# DSI1_A register map
Vendor: Texas Instruments
Peripheral module from a debugger description file (folder omap5430_ES2_PUBLIC).
Registers are 32-bit, access per field, reset 0x0 unless marked. A register's access mark holds for its fields unless they carry their own. Offsets are as the file gives them; lines under a group give offsets from that group; [hi:lo] are bit positions; {n}, {i} and the like mark numbered series; 'fields as' and 'values as' point back to an identical list; <NAME> marks a mode.

## DSI1_A (part 1 of 2)
0x00 DSI_REVISION ro reset not defined — IP Revision
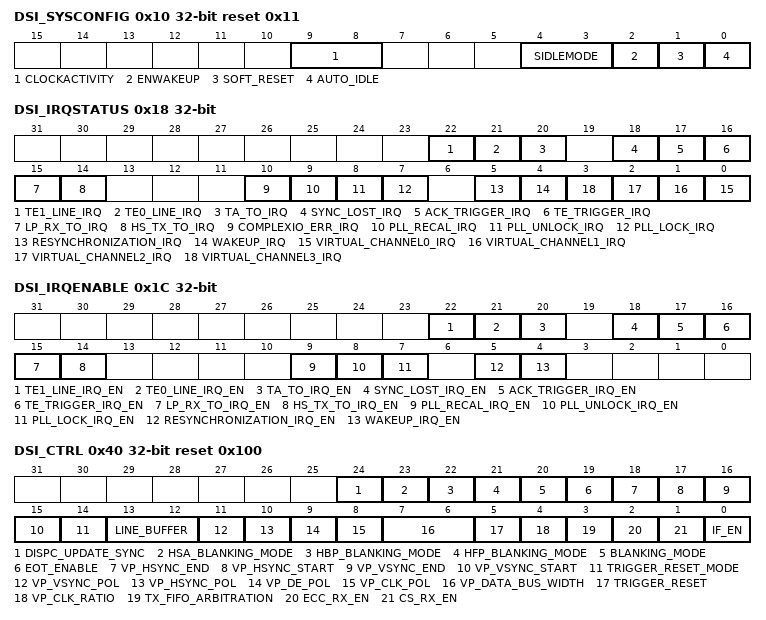
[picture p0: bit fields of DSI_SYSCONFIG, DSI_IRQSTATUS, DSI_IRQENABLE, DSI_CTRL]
0x10 DSI_SYSCONFIG reset 0x11 — System configuration register
  [9:8] CLOCKACTIVITY rw — Clock activity during wake-up mode period
    0=OCPFuncOff (Interface and functional clocks can be switched off.); 1=FuncOff (Functional clocks can be switched off and Interface clocks are maintained during wake-up period.); 2=OCPOff (Interface clocks can be switched off and functional clocks are maintained during wake-up period.); 3=OCPFuncOn (Interface and functional clocks are maintained during wake-up period.)
  [4:3] SIDLEMODE rw — Slave interface power management, Idle req/ack control
    0=fIdle (Force-idle. An idle request is acknowledged unconditionally.); 1=nIdle (No-idle. An idle request is never acknowledged.); 2=sIdle (Smart-idle. Acknowledgment to an idle request is given based on the internal activity of the module.)
  [2] ENWAKEUP rw — Wake-up mode enable bit
    0=WakeUpDis (Wakeup is disabled.); 1=WakeUpEnb (Wakeup is enabled.)
  [1] SOFT_RESET rw — Software reset. Set the bit to 1 to trigger a module reset. The bit is automatically reset by the hardware. During reads returns 0.
    0=Normal mode; 1=Reset (The module is reset.)
  [0] AUTO_IDLE rw — Internal interface gating strategy
    0=Free (Interface clock is free-running.); 1=Gated (Automatic Interface clock-gating strategy is applied based on the interface activity.)
0x14 DSI_SYSSTATUS ro reset 0x1 — System status register .
  [0] RESET_DONE — Internal reset monitoring
    0=ResetOngoing (Internal module reset is ongoing.); 1=ResetCompleted
0x18 DSI_IRQSTATUS — Interrupt status register – All virtual channels + DSI PHY + PLL
  [22] TE1_LINE_IRQ rw — The VSYNC and corresponding HSYNC pulses defined in DSI_TE_HSYNC_NUMBER for the line TE1 have been received by the DSI protocol engine and have triggeedr the start of the data transfer to the peripheral.
    0=False (Reads: Event is false. Writes: Status bit is unchanged.); 1=True (Reads: Event is true (pending). Writes: Status bit is reset.)
  [21] TE0_LINE_IRQ rw — The VSYNC and corresponding HSYNC pulses defined in DSI_TE_HSYNC_NUMBER for the line TE0 have been received by the DSI protocol engine and have triggered the start of the data transfer to the peripheral.
    values as TE1_LINE_IRQ
  [20] TA_TO_IRQ rw — Turnaround time-out
    values as TE1_LINE_IRQ
  [18] SYNC_LOST_IRQ rw — Synchronization with video port is lost (video mode only).
    values as TE1_LINE_IRQ
  [17] ACK_TRIGGER_IRQ rw — Acknowledge trigger
    values as TE1_LINE_IRQ
  [16] TE_TRIGGER_IRQ rw — Tearing effect trigger
    values as TE1_LINE_IRQ
  [15] LP_RX_TO_IRQ rw — Interrupt for low-power RX time-out
    values as TE1_LINE_IRQ
  [14] HS_TX_TO_IRQ rw — Interrupt for high-speed TX time-out
    values as TE1_LINE_IRQ
  [10] COMPLEXIO_ERR_IRQ ro — Error signaling from DSI PHY: status of the DSI PHY errors received from the DSI PHY (events are defined inDSI_COMPLEXIO_IRQSTATUS).
    0=False (Reads: Event is false.); 1=True (Reads: Event is true (pending).)
  [9] PLL_RECAL_IRQ rw — PLL recal event (assertion of DSIRecal signal from the DSI PLL control module)
    values as TE1_LINE_IRQ
  [8] PLL_UNLOCK_IRQ rw — PLL unclock event (deassertion of DSILock signal from the DSI PLL control module)
    values as TE1_LINE_IRQ
  [7] PLL_LOCK_IRQ rw — PLL clock event (assertion of DSILock signal from the DSI PLL control module)
    0=False (Reads: Event is false. Writes: Status bit unchanged.); 1=True (Reads: Event is true (pending). Writes: Status bit is reset.)
  [5] RESYNCHRONIZATION_IRQ rw — Video mode resynchronization indicates to software users that the video port works but the configuration of the timings for the display controller (DISPC) and DSI protocol engine may need to be modified to avoid resynchronization from occurring.
    values as TE1_LINE_IRQ
  [4] WAKEUP_IRQ rw — Wakeup
    values as TE1_LINE_IRQ
  [n] VIRTUAL_CHANNEL{n}_IRQ ro (n=0..3) — Virtual channel {n}
    values as COMPLEXIO_ERR_IRQ
0x1C DSI_IRQENABLE — Interrupt enable register – This register associates 1 bit for each virtual channel to enable or disable each virtual channel individually.
  [22] TE1_LINE_IRQ_EN rw — The VSYNC and corresponding HSYNC pulses defined in DSI_TE_HSYNC_NUMBER for the line TE1 have been received by the DSI protocol engine and have triggered the start of the data transfer to the peripheral.
    0=Disable (Event is masked.); 1=Enable (Event generates an interrupt when it occurs.)
  [21] TE0_LINE_IRQ_EN rw — The VSYNC and corresponding HSYNC pulses defined in DSI_TE_HSYNC_NUMBER for the line TE0 have been received by the DSI protocol engine and have triggered the start of the data transfer to the peripheral.
    values as TE1_LINE_IRQ_EN
  [20] TA_TO_IRQ_EN rw — Turnaround time-out
    values as TE1_LINE_IRQ_EN
  [18] SYNC_LOST_IRQ_EN rw — Synchronization with video port is lost (video mode only)
    values as TE1_LINE_IRQ_EN
  [17] ACK_TRIGGER_IRQ_EN rw — Acknowledge trigger
    values as TE1_LINE_IRQ_EN
  [16] TE_TRIGGER_IRQ_EN rw — Tearing effect trigger
    0=Disable (Event is masked..); 1=Enable (Event generates an interrupt when it occurs..)
  [15] LP_RX_TO_IRQ_EN rw — Interrupt for low-power RX time-out
    values as TE1_LINE_IRQ_EN
  [14] HS_TX_TO_IRQ_EN rw — Interrupt for high-speed TX time-out
    values as TE1_LINE_IRQ_EN
  [9] PLL_RECAL_IRQ_EN rw — PLL recal event (assertion of DSIRecal signal from the DSI PLL control module)
    values as TE1_LINE_IRQ_EN
  [8] PLL_UNLOCK_IRQ_EN rw — PLL unclock event (deassertion of DSILock signal from the DSI PLL control module)
    values as TE1_LINE_IRQ_EN
  [7] PLL_LOCK_IRQ_EN rw — PLL clock event (assertion of DSILock signal from the DSI PLL control module)
    values as TE1_LINE_IRQ_EN
  [5] RESYNCHRONIZATION_IRQ_EN rw — Video mode resynchronization
    values as TE1_LINE_IRQ_EN
  [4] WAKEUP_IRQ_EN rw — Wakeup
    values as TE1_LINE_IRQ_EN
0x40 DSI_CTRL reset 0x100 — Global control register – This register controls the DSI protocol engine module. This register mustnot be modified dynamically (except IF_EN bit fields).
  [24] DISPC_UPDATE_SYNC rw — Determines whether the Dispc_Update_Sync signal from the display controller is used
    0=Disable (Dispc_Update_Sync signal is not used.); 1=Enable (Dispc_Update_Sync signal is used.)
  [23] HSA_BLANKING_MODE rw — Blanking mode
    0=COMMAND_PACKET_TX_FIFO (Packets in TX FIFO are sent during HSA blanking period of video mode or LPS is used.); 1=HS_BLANKING_PACKET_ONLY (LONG BLANKING PACKETS only are used during HSA blanking period of video mode.)
  [22] HBP_BLANKING_MODE rw — Blanking mode
    0=COMMAND_PACKET_TX_FIFO (Packets in TX FIFO are sent during HBP blanking period of video mode or LPS is used.); 1=HS_BLANKING_PACKET_ONLY (LONG BLANKING PACKETS only are used during HBP blanking period of video mode.)
  [21] HFP_BLANKING_MODE rw — Blanking mode
    0=COMMAND_PACKET_TX_FIFO (Packets in TX FIFO are sent during HFP blanking period of video mode or LPS is used.); 1=HS_BLANKING_PACKET_ONLY (LONG BLANKING PACKETS only are used during HFP blanking period of video mode.)
  [20] BLANKING_MODE rw
    0=LPS (LPS is used during blanking periods of video mode (except HSA, HBP, HFP defined in HSA_BLANKING_MODE, HBP_BLANKING_MODE, and HFP_BLANKING_MODE, respectively) when there is no command mode data in TX FIFO ready to be sent. Thus, blanking periods can be different during the frame depending on the TX FIFO.); 1=HS (LONG BLANKING PACKETS are used during blanking periods of video mode (except HSA, HBP, HFP defined in HSA_BLANKING_MODE, HBP_BLANKING_MODE, and HFP_BLANKING_MODE, respectively) regardless of the packets present in the TX FIFO ready to be sent.)
  [19] EOT_ENABLE rw — Enable EOT packets at the end of HS transmission.
    0=EOT_OFF (No EOT packets); 1=EOT_ON (EOT packet is sent at all HS-to-LP transitions.)
  [18] VP_HSYNC_END rw — HSYNC end pulse
    0=Disabled. No HSYNC END short packet is generated.; 1=Enabled. While the HSYNC END pulse is detected, the associated short packet HSYNC END is generated.
  [17] VP_HSYNC_START rw — HSYNC start pulse.
    0=Disabled. No HSYNC START short packet is generated.; 1=Enabled. While the HSYNC start pulse is detected, the associated short packet HSYNC START is generated.
  [16] VP_VSYNC_END rw — VSYNC end pulse
    0=Disabled. No VSYNC END short packet is generated.; 1=Enabled. While the VSYNC END pulse is detected, the associated short packet VSYNC END is generated.
  [15] VP_VSYNC_START rw — VSYNC start pulse
    0=Disabled. No VSYNC START short packet is generated.; 1=Enabled. While the VSYNC START pulse is detected, the associated short packet VSYNC START is generated.
  [14] TRIGGER_RESET_MODE rw — Selection of the trigger reset modeThe principal is to wait for the current video frame to be transferred on the link. Any data received after the VSYNC are ignored. enum=Synchronized .
    0=Synchronized: The mode is valid only if there is virtual channel using the video mode and it is active; 1=Immediate: All pending requests in TX FIFO are taken into account for transfer scheduling, the RX FIFO is ignored, and the data from video port are ignored as soon as possible. Only the current transfer on DSI link and already scheduled ones are transmitted. All the other transfers are discarded.
  [13:12] LINE_BUFFER rw — Number of line buffers to be used while receiving data on the video port. The valid values are from 0 toDSI_GNQ[17:16] VP1_NB_LINE_BUFFER.
    0=f0 (No line buffer); 1=f1 (One line buffer); 2=f2 (Two line buffers)
  [11] VP_VSYNC_POL rw — VP vertical synchronization signal polarity
    0=Low (VSYNC signal on the video port is active low.); 1=High (VSYNC signal on the video port is active high.)
  [10] VP_HSYNC_POL rw — VP horizontal synchronization signal polarity
    0=Low (HSYNC signal on the video port is active low.); 1=High (HSYNC signal on the video port is active high.)
  [9] VP_DE_POL rw — VP data enable signal polarity
    0=Low (DE signal on the video port is active low.); 1=High (DE signal on the video port is active high.)
  [8] VP_CLK_POL rw — VP pixel clock polarity
    0=Falling (The DSI protocol engine module captures the data on the VP on the pixel clock falling edge. The module connected to the VP must drive the data on the pixel clock rising edge.); 1=Rising (The DSI protocol engine module captures the data on the VP on the pixel clock raising edge. The module connected to the VP must drive the data on the pixel clock falling edge.)
  [7:6] VP_DATA_BUS_WIDTH rw — Defines the size of the video port data bus
    0=f16 (16-bit data width (LSB of the 24-bit video port data bus)); 1=f18 (18-bit data width (LSB of the 24-bit video port data bus)); 2=f24 (24-bit data width (LSB of the 24-bit video port data bus))
  [5] TRIGGER_RESET rw — Send the reset trigger to the peripheral.
    0=Disable (Reads: Reset trigger generation is complete. It is reset by hardware when it completes. Writes: Cancellation of the request for reset trigger generation (may be too late because it is already ongoing)); 1=Enable (Reads: Generation of the reset trigger has been requested by the user (may be ongoing but not yet complete). Writes: Request for reset trigger to be sent to the peripheral)
  [4] VP_CLK_RATIO rw — The field indicates the clock ratio between VP_CLK and VP_PCLK. The clock VP_PCLK is generated from VP_CLK. It is divided down.The information is used only when the video port is used to provide data in command mode. In the case of video mode, it is not used. .
    0=RATIO2 (The clock VP_PCLK is the clock VP_CLK divided by 2. The duty cycle of VP_PCLK is 50/50.); 1=RATIO3ANDHIGHER (The clock VP_PCLK is the clock VP_CLK divided by 3 or more. The duty cycle of VP_PCLK is not 50/50 for odd ratio numbers (3 , 5, 7, ...).)
  [3] TX_FIFO_ARBITRATION rw — Defines the arbitration scheme for granting the virtual channel pending ready requests in the TX FIFO
    0=Round-robin scheme is used; 1=Sequential scheme is used
  [2] ECC_RX_EN rw — Enables the Error Correction Code check for the received header (short and long packets for all virtual channel ids).
    0=Disabled; 1=Enabled
  [1] CS_RX_EN rw — Enables the checksum check for the received payload (long packet only for all virtual channel ids)
    0=Disabled; 1=Enabled
  [0] IF_EN rw — Enables the module. When the module is disabled, the signals from the DSI PHY are gated (no updates of the interrupt status register).It is not possible to change the bit fields in the register except when IF_EN is enabled. All the other registers can be changed except those that require [0] VC_EN to be equal to 0 to be modified. .
    0=Disable (The interface is disabled. If one of the virtual channels uses the video mode with the video port to receive data, the DSI protocol engine is disabled when the next VSYNC is received and all the data in the FIFO for the other virtual channels in command mode are sent to the peripherals (if BTA_EN is enabled, the DSI protocol must wait for the response and BTA from the peripheral before disabling all the internal logic, because an acknowledge is requested).); 1=Enable (The interface is enabled immediately, and the data acquisition on the video port starts on the next VSYNC (video mode) or first data received in the slave port FIFO (command mode).)
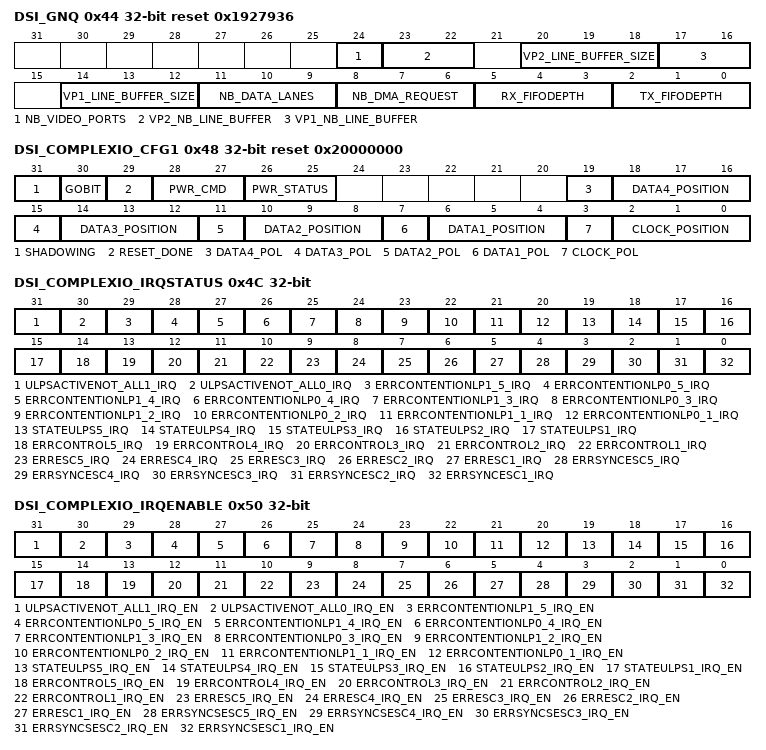
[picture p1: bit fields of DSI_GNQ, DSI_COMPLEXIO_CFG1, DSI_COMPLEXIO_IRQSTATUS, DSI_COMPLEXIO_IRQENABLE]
0x44 DSI_GNQ ro reset 0x1927936 — Generic parameter register – This register provide a way to read the generic parameters used in the design.
  [24] NB_VIDEO_PORTS — Number of video ports
    0=Single_VP (Only video port 1 is present.); 1=Dual_VP (Video port 1 and video port 2 are present.)
  [23:22] VP2_NB_LINE_BUFFER — Determines the number of video buffer lines associated to video port 2
    0=f0 (No line buffer); 1=f1 (One line buffer of the size defined in LINE_BUFFER_SIZE); 2=f2 (Two line buffers of the size defined in LINE_BUFFER_SIZE)
  [20:18] VP2_LINE_BUFFER_SIZE — Determines the video line buffer size associated to video port 2
    1=f1 (512 x 24 bits, 682 x 18 bits, 768 x 16 bits (memory of 384 x 32 bits)); 2=f2 (682 x 24 bits, 910 x 18 bits, 1024 x 16 bits (memory of 512 x 32 bits)); 3=f3 (853 x 24 bits, 1137 x 18 bits, 1280 x 16 bits (memory of 640 x 32 bits)); 4=f4 (1024 x 24 bits, 1365 x 18 bits, 1536 x 16 bits (memory of 768 x 32 bits)); 5=f5 (1194 x 24 bits, 1592 x 18 bits, 1792 x 16 bits (memory of 896 x 32 bits)); 6=f6 (1365 x 24 bits, 1820 x 18 bits, 2048 x 16 bits (memory of 1024 x 32 bits))
  [17:16] VP1_NB_LINE_BUFFER — Determines the number of video buffer lines associated to video port 1
    0=f0 (No line buffer); 1=f1 (1 line buffer of the size defined in LINE_BUFFER_SIZE); 2=f2 (2 line buffers of the size defined in LINE_BUFFER_SIZE)
  [14:12] VP1_LINE_BUFFER_SIZE — Determines the video line buffer size associated to video port 1
    1=f1 (512 x 24 bits, 682 x 18 bits, 768 x16 bits (memory of 384 x 32 bits)); 2=f2 (682 x 24 bits, 910 x 18 bits, 1024 x16 bits (memory of 512 x 32 bits)); 3=f3 (853 x 24 bits, 1137 x 18 bits, 1280 x16 bits (memory of 640 x 32 bits)); 4=f4 (1024 x 24 bits, 1365 x 18 bits, 1536 x16 bits (memory of 768 x 32 bits)); 5=f5 (1194 x 24 bits, 1592 x 18 bits, 1792 x16 bits (memory of 896 x 32 bits)); 6=f6 (1365 x 24 bits, 1820 x 18 bits, 2048 x16 bits (memory of 1024 x 32 bits)); 7=f7 (1920 x 24 bits, 2560 x 18 bits, 2880 x16 bits (memory of 1440 x 32 bits))
  [11:9] NB_DATA_LANES — Determines the number of data lanes supported by the DSI protocol engine
    1=f1 (One data lane); 2=f2 (Two data lanes); 3=f3 (Three data lanes); 4=f4 (Four data lanes)
  [8:6] NB_DMA_REQUEST — Determines the number of DMA_REQ signals
    0=f0 (No DMA request); 1=f1 (One DMA request); 2=f2 (Two DMA requests); 3=f3 (Three DMA requests); 4=f4 (Four DMA requests)
  [5:3] RX_FIFODEPTH — Determines the data RX FIFO depth (32-bit words) on the slave port
    4=f32 (32x 33 bits); 5=f64 (64x 33 bits); 6=f128 (128 x 33 bits); 7=f256 (256 x 33 bits)
  [2:0] TX_FIFODEPTH — Determines the data TX FIFO depth (33-bit words) on the slave port
    values as RX_FIFODEPTH
0x48 DSI_COMPLEXIO_CFG1 reset 0x20000000 — Complexio configuration register for the DSI PHY.
  [31] SHADOWING rw — Shadowing configuration
    0=Disabled. The writes to the through registers are done like the other SCP registers.; 1=Enabled. The writes to the through registers are done only when the GOBIT is set and when the signal DISPCUpdataSync from the display controller module is active.
  [30] GOBIT rw — Allows the synchronized update of the shadow registers when the signal DISPCUpdateSync is active.
    0=Resets the GOBIT. The hardware has finished the update of the shadow SCP registers. The bit is reset by hardware. The software can reset the bit if the user decides to abort it. There is no guarantee that the software reset is done before the transfer of the values to the DSI PHY.; 1=Set (Set the GOBIT. Only when the transfer of the new values for the three first registers is completed (3, 2, 1, or 0 transfers are performed based on the number of registers to update), the GOBIT is reset. The DISPCUpdateSync signal is used to synchronize the update. The bit must be set only when it is in reset state.)
  [29] RESET_DONE ro — Internal reset monitoring of the power domain using the TXBYTECLKHS clock from the DSI PHY
    values as DSI_SYSSTATUS.RESET_DONE
  [28:27] PWR_CMD rw — Command for power control of the DSI PHY
    0=STATE_OFF (Command to change to OFF state); 1=STATE_ON (Command to change to ON state); 2=STATE_ULP (Command to change to ULTRALOW-POWER state)
  [26:25] PWR_STATUS ro — Status of the power control of the DSI PHY
    0=STATE_OFF (DSI PHY in OFF state); 1=STATE_ON (DSI PHY in ON state); 2=STATE_ULP (DSI PHY in ULTRALOW-POWER state)
  [19] DATA4_POL rw — ± differential pin order of the fourth data lane
    0=±_pin_order_(DSI.DX_=_+_and_DSi.DY_=_–); 1=±_pin_order_(DSI.DX=_–_and_DSi.DY_=_+)
  [18:16] DATA4_POSITION rw — Position and order of the fourth data lane
    0=Not_used/connected; 1=The fourth data lane is at the first position (first lane is lane 0); 2=The fourth data lane is at the second position (second lane is lane 1); 3=The fourth data lane is at the third position (third lane is lane 2); 4=The fourth data lane is at the fourth position (fourth lane is lane 3); 5=The fourth data lane is at the fifth position (fifth lane is lane 4)
  [15] DATA3_POL rw — ± differential pin order of the third data lane
    0=±_pin_order_(DSI.DX_=_+_and_DSi.DY_=_–); 1=±_pin_order_(DSI.DX_=_–_and_DSi.DY_=_+)
  [14:12] DATA3_POSITION rw — Position and order of the third data lane
    0=Not_used/connected; 1=The third data lane is at the first position (first lane is lane 0); 2=The third data lane is at the second position (second lane is lane 1); 3=The third data lane is at the third position (third lane is lane 2); 4=The third data lane is at the fourth position 4 (fourth lane is lane 3); 5=The third data lane is at the fifth position (fifth lane is lane 4)
  [11] DATA2_POL rw — ± differential pin order of the seond data lane
    0=PlusMinus (± pin order (DSI.DX = + and DSi.DY = –)); 1=MinusPlus (± pin order (DSI.DX = – and DSi.DY = +))
  [10:8] DATA2_POSITION rw — Position and order of the second data lane
    0=Not used/connected; 1=Position_1 (The second data lane is at the first position (first lane is lane 0).); 2=Position_2 (The second data lane is at the second position (second lane is lane 1).); 3=Position_3 (The second data lane is at the third position (third lane is lane 2).); 4=Position_4 (The second data lane is at the fourth position (fourth lane is lane 3).); 5=Position_5 (The second data lane is at the fifth position (fifth lane is lane 4).)
  [7] DATA1_POL rw — ± pin differential pin order of the first data lane
    values as DATA2_POL
  [6:4] DATA1_POSITION rw — Position and order of the first data lane. The first data lane s always present.
    0=Not_used/connected; 1=Position_1 (The first data lane is at the first position (first lane is lane 0).); 2=Position_2 (The first data lane is at the second position (second lane is lane 1).); 3=Position_3 (The first data lane is at the third position (third lane is lane 2).); 4=Position_4 (The first data lane is at the fourth position (fourth lane is lane 3).); 5=Position_5 (The first data lane is at the fifth position (fifth lane is lane 4).)
  [3] CLOCK_POL rw — ± differential pin order of the clock lane
    values as DATA2_POL
  [2:0] CLOCK_POSITION rw — Position and order of the clock lane; 0, 5, 6, and 7 are reserved. The clock lane is always present but cannot be at the fifth position even if the DSI PHY consists of five lanes.
    0=Not_used/connected; 1=Position_1 (Clock lane is at the first position (first lane is lane 0).); 2=Position_2 (Clock lane is at the second position (second lane is lane 1).); 3=Position_3 (Clock lane is at the third position (third lane is lane 2).); 4=Position_4 (Clock lane is at the fourth position (fourth lane is lane 3).); 5=Position_4 (Reserved); 6=Position_4 (Reserved); 7=Position_4 (Reserved)
0x4C DSI_COMPLEXIO_IRQSTATUS rw — Interrupt status register – All errors from DSI PHY
  [31] ULPSACTIVENOT_ALL1_IRQ — All the ULPSActiveNOT signals corresponding to the lanes with TXULPSExit being high are high.
    values as DSI_IRQSTATUS.PLL_LOCK_IRQ
  [30] ULPSACTIVENOT_ALL0_IRQ — All signals ULPSActiveNOT are 0
    values as DSI_IRQSTATUS.PLL_LOCK_IRQ
  [29] ERRCONTENTIONLP1_5_IRQ — Contention LP1 error for the fifth lane
    0=Reads: Event is false. Writes: Status bit unchanged.; 1=Reads: Event is true (pending). Writes: Status bit is reset.
  [28] ERRCONTENTIONLP0_5_IRQ — Contention LP0 error for the fifth lane
    values as ERRCONTENTIONLP1_5_IRQ
  [27] ERRCONTENTIONLP1_4_IRQ — Contention LP1 error for the fourth lane
    values as ERRCONTENTIONLP1_5_IRQ
  [26] ERRCONTENTIONLP0_4_IRQ — Contention LP0 error for the fourth lane
    values as ERRCONTENTIONLP1_5_IRQ
  [25] ERRCONTENTIONLP1_3_IRQ — Contention LP1 error for the third lane
    values as DSI_IRQSTATUS.PLL_LOCK_IRQ
  [24] ERRCONTENTIONLP0_3_IRQ — Contention LP0 error for the third lane
    values as DSI_IRQSTATUS.PLL_LOCK_IRQ
  [23] ERRCONTENTIONLP1_2_IRQ — Contention LP1 error for the second lane
    values as DSI_IRQSTATUS.PLL_LOCK_IRQ
  [22] ERRCONTENTIONLP0_2_IRQ — Contention LP0 error for the second lane
    values as DSI_IRQSTATUS.PLL_LOCK_IRQ
  [21] ERRCONTENTIONLP1_1_IRQ — Contention LP1 error for the first lane
    values as DSI_IRQSTATUS.PLL_LOCK_IRQ
  [20] ERRCONTENTIONLP0_1_IRQ — Contention LP0 error for the first lane
    values as DSI_IRQSTATUS.PLL_LOCK_IRQ
  [19] STATEULPS5_IRQ — the fifth lane in ULTRALOW-POWER State
    values as ERRCONTENTIONLP1_5_IRQ
  [18] STATEULPS4_IRQ — the fourth lane in ultralow-power mode
    values as ERRCONTENTIONLP1_5_IRQ
  [17] STATEULPS3_IRQ — the third lane in ULTRALOW-POWER state
    values as DSI_IRQSTATUS.PLL_LOCK_IRQ
  [16] STATEULPS2_IRQ — the second lane in ULTRALOW-POWER state
    values as DSI_IRQSTATUS.PLL_LOCK_IRQ
  [15] STATEULPS1_IRQ — the first lane in ULTRALOW-POWER state
    values as DSI_IRQSTATUS.PLL_LOCK_IRQ
  [14] ERRCONTROL5_IRQ — Control error for the fifth lane
    values as ERRCONTENTIONLP1_5_IRQ
  [13] ERRCONTROL4_IRQ — Control error for the fourth lane
    values as ERRCONTENTIONLP1_5_IRQ
  [12] ERRCONTROL3_IRQ — Control error for the third lane
    values as DSI_IRQSTATUS.PLL_LOCK_IRQ
  [11] ERRCONTROL2_IRQ — Control error for the second lane
    values as DSI_IRQSTATUS.PLL_LOCK_IRQ
  [10] ERRCONTROL1_IRQ — Control error for the first lane
    values as DSI_IRQSTATUS.PLL_LOCK_IRQ
  [9] ERRESC5_IRQ — Escape entry error for the fifth lane
    values as ERRCONTENTIONLP1_5_IRQ
  [8] ERRESC4_IRQ — Escape entry error for the fourth lane
    values as ERRCONTENTIONLP1_5_IRQ
  [7] ERRESC3_IRQ — Escape entry error for the third lane
    values as DSI_IRQSTATUS.PLL_LOCK_IRQ
  [6] ERRESC2_IRQ — Escape entry error for the second lane
    values as DSI_IRQSTATUS.PLL_LOCK_IRQ
  [5] ERRESC1_IRQ — Escape entry error for the first lane
    values as DSI_IRQSTATUS.PLL_LOCK_IRQ
  [4] ERRSYNCESC5_IRQ — Low power Data transmission synchronization error for the fifth lane
    values as ERRCONTENTIONLP1_5_IRQ
  [3] ERRSYNCESC4_IRQ — Low power Data transmission synchronization error for the fourth lane
    values as ERRCONTENTIONLP1_5_IRQ
  [2] ERRSYNCESC3_IRQ — Low power Data transmission synchronization error for the third lane
    values as DSI_IRQSTATUS.PLL_LOCK_IRQ
  [1] ERRSYNCESC2_IRQ — Low power Data transmission synchronization error for the second lane
    values as DSI_IRQSTATUS.PLL_LOCK_IRQ
  [0] ERRSYNCESC1_IRQ — Low power Data transmission synchronization error for the first lane
    values as DSI_IRQSTATUS.PLL_LOCK_IRQ
0x50 DSI_COMPLEXIO_IRQENABLE rw — INTERRUPT ENABLE REGISTER - All errors from DSI PHY
  [31] ULPSACTIVENOT_ALL1_IRQ_EN — All the ULPSActiveNOT signals corresponding to the lanes with TXULPSExit being high are high.
    0=Disable (Event is masked); 1=Enable (Event generates an interrupt when it occurs)
  [30] ULPSACTIVENOT_ALL0_IRQ_EN — All signals ULPSActiveNOT are 0
    values as ULPSACTIVENOT_ALL1_IRQ_EN
  [29] ERRCONTENTIONLP1_5_IRQ_EN — Contention LP1 error for the fifth lane
    0=Event_is_masked; 1=Event generates an interrupt when it occurs
  [28] ERRCONTENTIONLP0_5_IRQ_EN — Contention LP0 error for the fifth lane
    values as ERRCONTENTIONLP1_5_IRQ_EN
  [27] ERRCONTENTIONLP1_4_IRQ_EN — Contention LP1 error for the fourth lane
    values as ERRCONTENTIONLP1_5_IRQ_EN
  [26] ERRCONTENTIONLP0_4_IRQ_EN — Contention LP0 error for the fourth lane
    values as ERRCONTENTIONLP1_5_IRQ_EN
  [25] ERRCONTENTIONLP1_3_IRQ_EN — Contention LP1 error for the third lane
    values as ULPSACTIVENOT_ALL1_IRQ_EN
  [24] ERRCONTENTIONLP0_3_IRQ_EN — Contention LP0 error for the third lane
    values as ULPSACTIVENOT_ALL1_IRQ_EN
  [23] ERRCONTENTIONLP1_2_IRQ_EN — Contention LP1 error for the second lane
    values as ULPSACTIVENOT_ALL1_IRQ_EN
  [22] ERRCONTENTIONLP0_2_IRQ_EN — Contention LP0 error for the second lane
    values as ULPSACTIVENOT_ALL1_IRQ_EN
  [21] ERRCONTENTIONLP1_1_IRQ_EN — Contention LP1 error for the first lane
    values as ULPSACTIVENOT_ALL1_IRQ_EN
  [20] ERRCONTENTIONLP0_1_IRQ_EN — Contention LP0 error for the first lane
    values as ULPSACTIVENOT_ALL1_IRQ_EN
  [19] STATEULPS5_IRQ_EN — the fifth lane in ULTRALOW-POWER state
    values as ERRCONTENTIONLP1_5_IRQ_EN
  [18] STATEULPS4_IRQ_EN — the fourth lane in ULTRALOW-POWER state
    values as ERRCONTENTIONLP1_5_IRQ_EN
  [17] STATEULPS3_IRQ_EN — the third lane in ULTRALOW-POWER state
    values as ULPSACTIVENOT_ALL1_IRQ_EN
  [16] STATEULPS2_IRQ_EN — the second lane in ULTRALOW-POWER state
    values as ULPSACTIVENOT_ALL1_IRQ_EN
  [15] STATEULPS1_IRQ_EN — the first lane in ULTRALOW-POWER state
    values as ULPSACTIVENOT_ALL1_IRQ_EN
  [14] ERRCONTROL5_IRQ_EN — Control error for the fifth lane
    values as ERRCONTENTIONLP1_5_IRQ_EN
  [13] ERRCONTROL4_IRQ_EN — Control error for the fourth lane
    values as ERRCONTENTIONLP1_5_IRQ_EN
  [12] ERRCONTROL3_IRQ_EN — Control error for the third lane
    values as ULPSACTIVENOT_ALL1_IRQ_EN
  [11] ERRCONTROL2_IRQ_EN — Control error for the second lane
    values as ULPSACTIVENOT_ALL1_IRQ_EN
  [10] ERRCONTROL1_IRQ_EN — Control error for the first lane
    values as ULPSACTIVENOT_ALL1_IRQ_EN
  [9] ERRESC5_IRQ_EN — Escape entry error for the fifth lane
    values as ERRCONTENTIONLP1_5_IRQ_EN
  [8] ERRESC4_IRQ_EN — Escape entry error for the fourth lane
    values as ERRCONTENTIONLP1_5_IRQ_EN
  [7] ERRESC3_IRQ_EN — Escape entry error for the third lane
    values as ULPSACTIVENOT_ALL1_IRQ_EN
  [6] ERRESC2_IRQ_EN — Escape entry error for the second lane
    values as ULPSACTIVENOT_ALL1_IRQ_EN
  [5] ERRESC1_IRQ_EN — Escape entry error for the first lane
    values as ULPSACTIVENOT_ALL1_IRQ_EN
  [4] ERRSYNCSESC5_IRQ_EN — Low power Data transmission synchronization error for the fifth lane
    values as ERRCONTENTIONLP1_5_IRQ_EN
  [3] ERRSYNCSESC4_IRQ_EN — Low power Data transmission synchronization error for the fourth lane
    values as ERRCONTENTIONLP1_5_IRQ_EN
  [2] ERRSYNCSESC3_IRQ_EN — Low power Data transmission synchronization error for the third lane
    values as ULPSACTIVENOT_ALL1_IRQ_EN
  [1] ERRSYNCSESC2_IRQ_EN — Low power Data transmission synchronization error for the second lane
    values as ULPSACTIVENOT_ALL1_IRQ_EN
  [0] ERRSYNCSESC1_IRQ_EN — Low power Data transmission synchronization error for the first lane
    values as ULPSACTIVENOT_ALL1_IRQ_EN
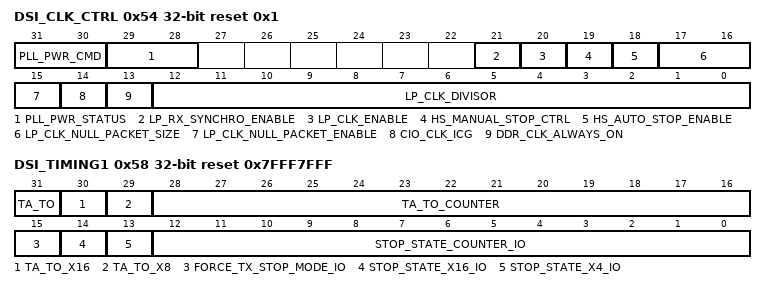
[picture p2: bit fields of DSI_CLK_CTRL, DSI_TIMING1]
0x54 DSI_CLK_CTRL reset 0x1 — CLOCK CONTROL This register controls the CLOCK GENERATION. The register can be modified only when IF_EN is reset.
  [31:30] PLL_PWR_CMD rw — Command for power control of the DSI PLL Control module
    0=STATE_OFF (Command to change to OFF state); 1=STATE_ON_HSCLK (Command to change to ON state for PLL only (HSDIVISER is OFF)); 2=STATE_ON_ALL (Command to change to ON state for both PLL and HSDIVISER); 3=STATE_ON_DIV (Command to change to ON state for both PLL and HSDIVISER (no clock output to the DSI PHY))
  [29:28] PLL_PWR_STATUS ro — Status of the power control of the DSI PLL Control module
    0=STATE_OFF (DSI PLL Control module in OFF state); 1=STATE_ON_HSCLK (DSI PLL Control module in ON state for PLL only (HSDIVISER is OFF)); 2=STATE_ON_ALL (DSI PLL Control module in ON state for both PLL and HSDIVISER); 3=STATE_ON_DIV (DSI PLL Control module in ON state for both PLL and HSDIVISER (no clock output to the DSI PHY))
  [21] LP_RX_SYNCHRO_ENABLE rw — Defines if the functional is higher or lower than 30 MHz. The information is used to define synchronization to be used for RxValidEsc.
    0=LowSpeed (The DSI functional clock is equal or slower than 30 MHz. The synchronization is falling/rising.); 1=HighSpeed (The DSI functional clock is higher than 30 MHz. The synchronization is rising/rising.)
  [20] LP_CLK_ENABLE rw — Controls the gating of the TXCLKESC clock.
    0=Disabled. The clock is not generated. The value of LP_CLK_DIVISOR is not used and does not need to be programmed.; 1=Enabled. The clock is generated. The value of LP_CLK_DIVISOR is used and needs to be programmed.
  [19] HS_MANUAL_STOP_CTRL rw — In case HS_AUTO_STOP_ENABLE=0, the bit field allows manual control of the assertion/de-assertion of the signal DSIStopClk by the user.
    0=Deassertion (DSIStopClk de-assertion unconditionally.); 1=Assertion (DSIStopClk assertion unconditionally.)
  [18] HS_AUTO_STOP_ENABLE rw — Enables the automatic assertion/de-assertion of DSIStopClk signal.
    0=Disable (Auto mode disabled.); 1=Enable (Auto mode enabled.)
  [17:16] LP_CLK_NULL_PACKET_SIZE rw — Indicates the size of LP NULL Packets to be sent automatically when after the last LP packet transfer. It is used by the receiver to drain its internal pipeline. The valid values are from 0 to 3 bytes for the payload size.
  [15] LP_CLK_NULL_PACKET_ENABLE rw — Enables the generation of NULL packet in low speed.
    0=Disabled. The NULL packet is not sent in LP mode after the last LP packet.; 1=Enabled. The NULL packet is sent in LP mode after the last LP packet.
  [14] CIO_CLK_ICG rw — Gates SCPClk clock provided to DSI_PHY_DSS_x and PLL-CTRL module.
    0=Disabled. SCPClk is not generated. It remains at 0.; 1=Enabled. SCPClk is generated (OCP_CLK/4)
  [13] DDR_CLK_ALWAYS_ON rw — Defines if the DDR clock is also sent when there is no HS packets sent to the peripheral (low-power mode). So TXRequest for the clock lane is not de-asserted.
    0=Disabled. The DDR clock is only provided when HS packets are sent.; 1=Enabled. The DDR clock is always sent to the peripheral regardless of the state of the data lanes (HS or LS mode).
  [12:0] LP_CLK_DIVISOR rw — Defines the ratio to be used for the generation of the low-power mode clock from DSI functional clock. The supported values are from 1 to 8191(the value 0 is invalid). The output frequency shall be in the range between 20 MHz and 32 kHz.
0x58 DSI_TIMING1 rw reset 0x7FFF7FFF — TIMING1 REGISTER This register controls the DSI Protocol Engine module timers. Any bit field can be modified while [0] IF_EN is set to '1'. It is used to indicate the number of DSI1_A_CLK and DSI1_A_CLK functional clocks cycles for the timers FORCE_TX_STOP_TIMER and TA_TO_TIMER
  [31] TA_TO — Enables the turn-around timer
    0=Deassertion (Turn-around counter is disabled.); 1=Assertion (Turn-around counter is enabled (required to receive TA interrupt in case the turn-around procedure is not successful).)
  [30] TA_TO_X16 — Multiplication factor for the number of DSI_CLK functional clocks cycles defined in TA_TO_COUNTER bit field
    0=Disable (The number of DSI_CLK functional clock cycles defined in TA_TO_COUNTER is multiplied by 1x); 1=Enable (The number of DSI_CLK functional clock cycles defined in TA_TO_COUNTER is multiplied by 16x)
  [29] TA_TO_X8 — Multiplication factor for the number of DSI_CLK functional clock cycles defined in TA_TO_COUNTER bit field
    0=Disable (The number of DSI_CLK functional clock cycles defined in TA_TO_COUNTER is multiplied by 1x); 1=Enable (The number of DSI_CLK functional clock cycles defined in TA_TO_COUNTER is multiplied by 8x)
  [28:16] TA_TO_COUNTER — Turn around counter. It indicates the number of DSI_CLK function clock to wait for the change of the Direction PPI signal according to the TurnRequest signal The value is from 0 to 8191.
  [15] FORCE_TX_STOP_MODE_IO — Control of ForceTxStopMode signal
    0=Deassertion of ForceTxStopMode. The hardware reset the bit at the end of the ForceTXStopMode assertion. The software can reset the bit in order to stop the assertion of the ForceTXStopMode signal prior to the completion of the period.; 1=Assertion of ForceTxStopMode
  [14] STOP_STATE_X16_IO — Multiplication factor for the number of DSI_CLK functional clock cycles defined in STOP_STATE_COUNTER_IO bit field
    0=Disable (The number of DSI_CLK functional clock cycles defined in STOP_STATE _COUNTER_IO is multiplied by 1x); 1=Enable (The number of DSI_CLK functional clock cycles defined in STOP_STATE _COUNTER_IO is multiplied by 16x)
  [13] STOP_STATE_X4_IO — Multiplication factor for the number of DSI_CLK functional clock cycles defined in STOP_STATE_COUNTER_IO bit field
    0=Disable (The number of DSI_CLK functional clock cycles defined in STOP_STATE _COUNTER is multiplied by 1x); 1=Enable (The number of DSI_CLK functional clock cycles defined in STOP_STATE _COUNTER_IO is multiplied by 4x)
  [12:0] STOP_STATE_COUNTER_IO — Stop state counter. It indicates the number of DSI_CLK function clock to assert ForceTXStopMode signal. The value is from 0 to 8191.
